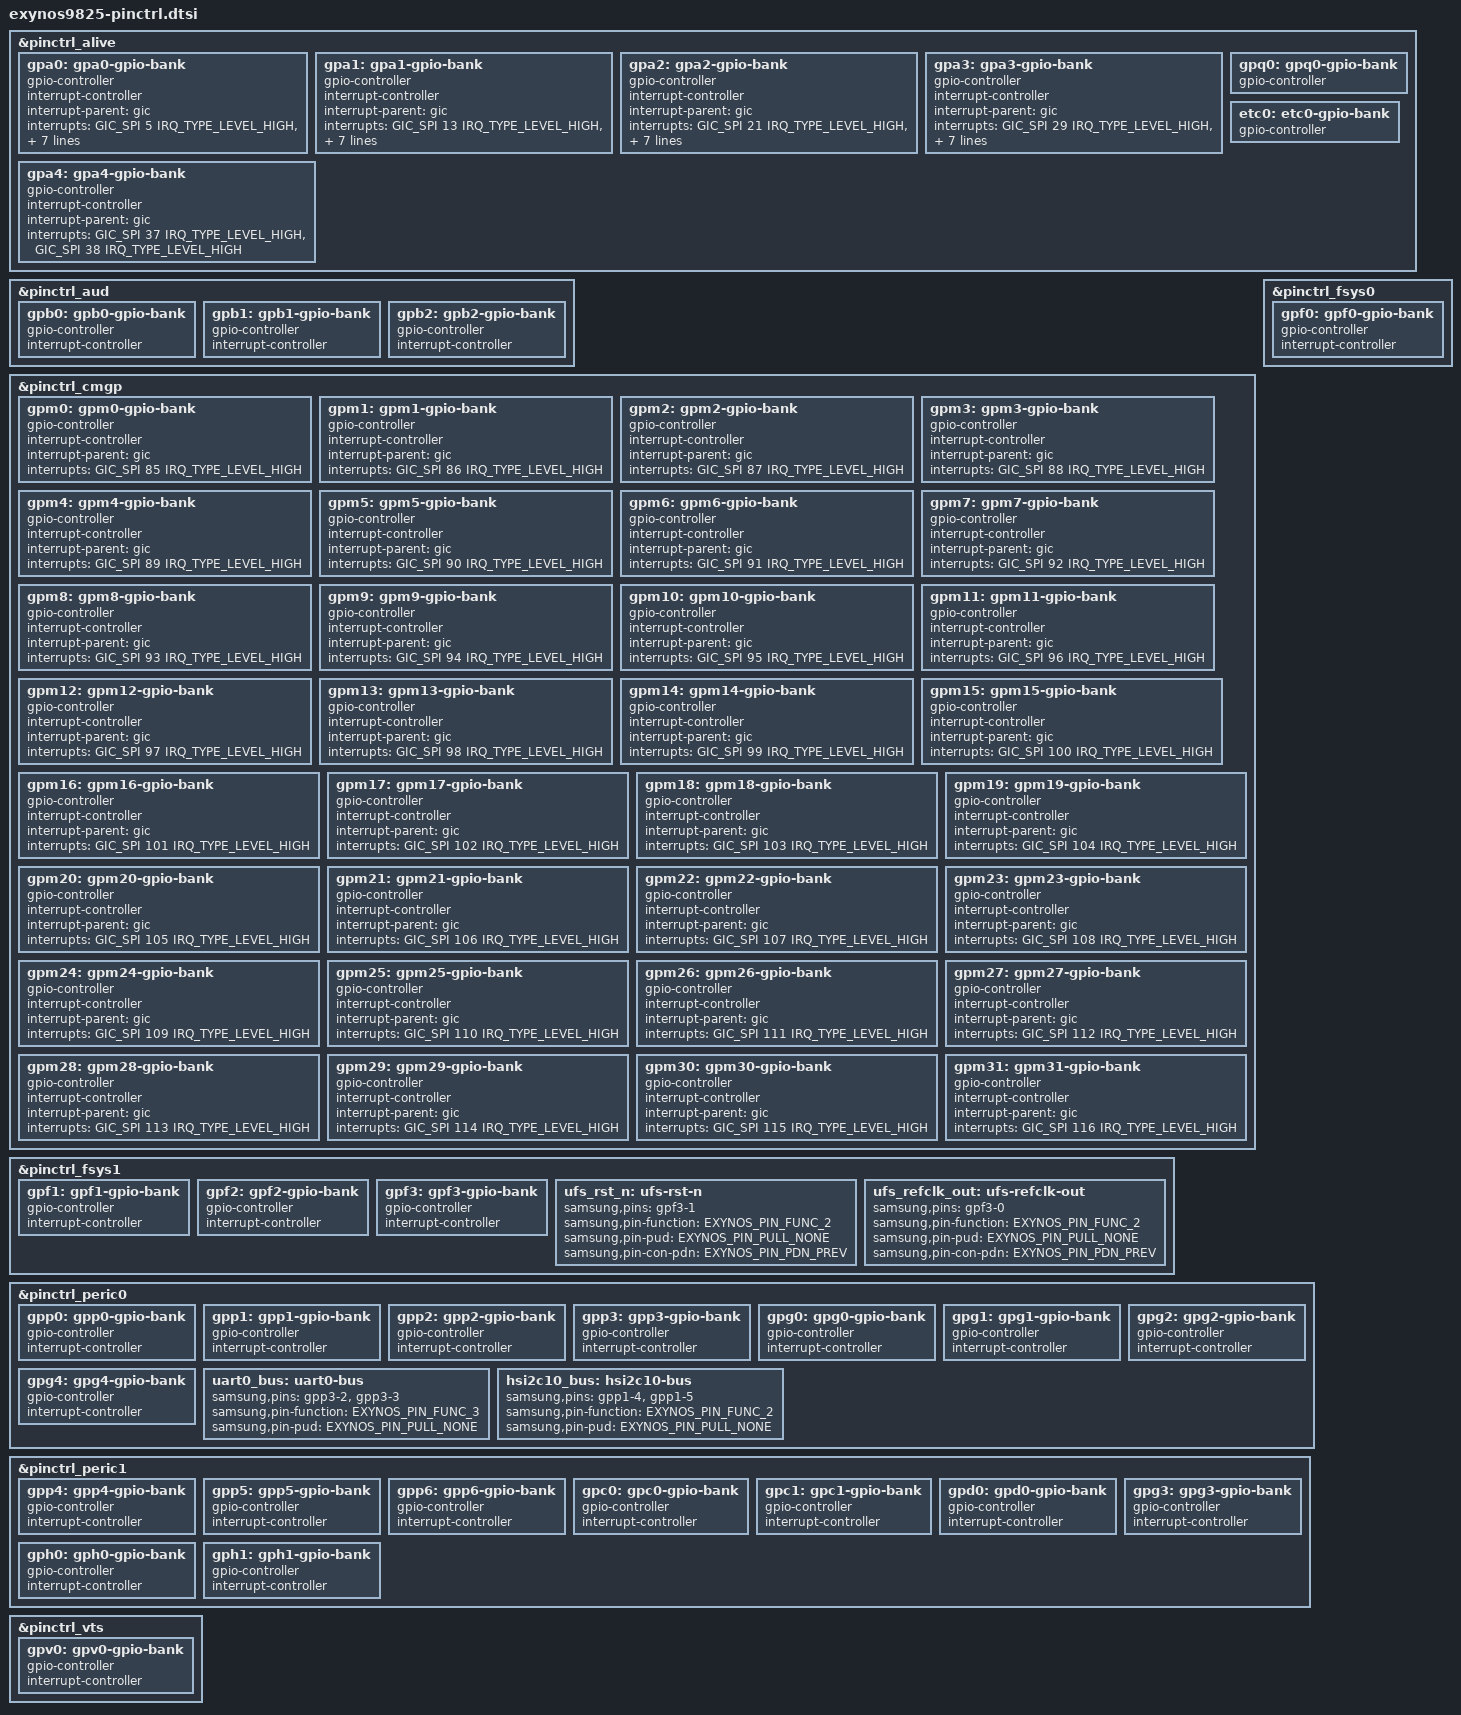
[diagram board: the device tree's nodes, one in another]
// SPDX-License-Identifier: GPL-2.0
/*
 * Samsung Exynos 9825 pin-mux and pin-config device tree source
 */

#include <dt-bindings/interrupt-controller/arm-gic.h>
#include "exynos-pinctrl.h"

&pinctrl_alive {
	gpa0: gpa0-gpio-bank {
		gpio-controller;
		#gpio-cells = <2>;

		interrupt-controller;
		#interrupt-cells = <2>;
		interrupt-parent = <&gic>;
		interrupts =
<GIC_SPI 5 IRQ_TYPE_LEVEL_HIGH>,
			     <GIC_SPI 6 IRQ_TYPE_LEVEL_HIGH>,
			     <GIC_SPI 7 IRQ_TYPE_LEVEL_HIGH>,
			     <GIC_SPI 8 IRQ_TYPE_LEVEL_HIGH>,
			     <GIC_SPI 9 IRQ_TYPE_LEVEL_HIGH>,
			     <GIC_SPI 10 IRQ_TYPE_LEVEL_HIGH>,
			     <GIC_SPI 11 IRQ_TYPE_LEVEL_HIGH>,
			     <GIC_SPI 12 IRQ_TYPE_LEVEL_HIGH>;
	};
	gpa1: gpa1-gpio-bank {
		gpio-controller;
		#gpio-cells = <2>;

		interrupt-controller;
		#interrupt-cells = <2>;
		interrupt-parent = <&gic>;
		interrupts =
<GIC_SPI 13 IRQ_TYPE_LEVEL_HIGH>,
			     <GIC_SPI 14 IRQ_TYPE_LEVEL_HIGH>,
			     <GIC_SPI 15 IRQ_TYPE_LEVEL_HIGH>,
			     <GIC_SPI 16 IRQ_TYPE_LEVEL_HIGH>,
			     <GIC_SPI 17 IRQ_TYPE_LEVEL_HIGH>,
			     <GIC_SPI 18 IRQ_TYPE_LEVEL_HIGH>,
			     <GIC_SPI 19 IRQ_TYPE_LEVEL_HIGH>,
			     <GIC_SPI 20 IRQ_TYPE_LEVEL_HIGH>;
	};
	gpa2: gpa2-gpio-bank {
		gpio-controller;
		#gpio-cells = <2>;

		interrupt-controller;
		#interrupt-cells = <2>;
		interrupt-parent = <&gic>;
		interrupts =
<GIC_SPI 21 IRQ_TYPE_LEVEL_HIGH>,
			     <GIC_SPI 22 IRQ_TYPE_LEVEL_HIGH>,
			     <GIC_SPI 23 IRQ_TYPE_LEVEL_HIGH>,
			     <GIC_SPI 24 IRQ_TYPE_LEVEL_HIGH>,
			     <GIC_SPI 25 IRQ_TYPE_LEVEL_HIGH>,
			     <GIC_SPI 26 IRQ_TYPE_LEVEL_HIGH>,
			     <GIC_SPI 27 IRQ_TYPE_LEVEL_HIGH>,
			     <GIC_SPI 28 IRQ_TYPE_LEVEL_HIGH>;
	};
	gpa3: gpa3-gpio-bank {
		gpio-controller;
		#gpio-cells = <2>;

		interrupt-controller;
		#interrupt-cells = <2>;
		interrupt-parent = <&gic>;
		interrupts =
<GIC_SPI 29 IRQ_TYPE_LEVEL_HIGH>,
			     <GIC_SPI 30 IRQ_TYPE_LEVEL_HIGH>,
			     <GIC_SPI 31 IRQ_TYPE_LEVEL_HIGH>,
			     <GIC_SPI 32 IRQ_TYPE_LEVEL_HIGH>,
			     <GIC_SPI 33 IRQ_TYPE_LEVEL_HIGH>,
			     <GIC_SPI 34 IRQ_TYPE_LEVEL_HIGH>,
			     <GIC_SPI 35 IRQ_TYPE_LEVEL_HIGH>,
			     <GIC_SPI 36 IRQ_TYPE_LEVEL_HIGH>;
	};
	gpa4: gpa4-gpio-bank {
		gpio-controller;
		#gpio-cells = <2>;

		interrupt-controller;
		#interrupt-cells = <2>;
		interrupt-parent = <&gic>;
		interrupts =
<GIC_SPI 37 IRQ_TYPE_LEVEL_HIGH>,
			     <GIC_SPI 38 IRQ_TYPE_LEVEL_HIGH>;
	};
	gpq0: gpq0-gpio-bank {
		gpio-controller;
		#gpio-cells = <2>;
	};
	etc0: etc0-gpio-bank {
		gpio-controller;
		#gpio-cells = <2>;
	};
};

&pinctrl_aud {
	gpb0: gpb0-gpio-bank {
		gpio-controller;
		#gpio-cells = <2>;

		interrupt-controller;
		#interrupt-cells = <2>;
	};
	gpb1: gpb1-gpio-bank {
		gpio-controller;
		#gpio-cells = <2>;

		interrupt-controller;
		#interrupt-cells = <2>;
	};
	gpb2: gpb2-gpio-bank {
		gpio-controller;
		#gpio-cells = <2>;

		interrupt-controller;
		#interrupt-cells = <2>;
	};
};

&pinctrl_cmgp {
	gpm0: gpm0-gpio-bank {
		gpio-controller;
		#gpio-cells = <2>;

		interrupt-controller;
		#interrupt-cells = <2>;
		interrupt-parent = <&gic>;
		interrupts =
<GIC_SPI 85 IRQ_TYPE_LEVEL_HIGH>;
	};
	gpm1: gpm1-gpio-bank {
		gpio-controller;
		#gpio-cells = <2>;

		interrupt-controller;
		#interrupt-cells = <2>;
		interrupt-parent = <&gic>;
		interrupts =
<GIC_SPI 86 IRQ_TYPE_LEVEL_HIGH>;
	};
	gpm2: gpm2-gpio-bank {
		gpio-controller;
		#gpio-cells = <2>;

		interrupt-controller;
		#interrupt-cells = <2>;
		interrupt-parent = <&gic>;
		interrupts =
<GIC_SPI 87 IRQ_TYPE_LEVEL_HIGH>;
	};
	gpm3: gpm3-gpio-bank {
		gpio-controller;
		#gpio-cells = <2>;

		interrupt-controller;
		#interrupt-cells = <2>;
		interrupt-parent = <&gic>;
		interrupts =
<GIC_SPI 88 IRQ_TYPE_LEVEL_HIGH>;
	};
	gpm4: gpm4-gpio-bank {
		gpio-controller;
		#gpio-cells = <2>;

		interrupt-controller;
		#interrupt-cells = <2>;
		interrupt-parent = <&gic>;
		interrupts =
<GIC_SPI 89 IRQ_TYPE_LEVEL_HIGH>;
	};
	gpm5: gpm5-gpio-bank {
		gpio-controller;
		#gpio-cells = <2>;

		interrupt-controller;
		#interrupt-cells = <2>;
		interrupt-parent = <&gic>;
		interrupts =
<GIC_SPI 90 IRQ_TYPE_LEVEL_HIGH>;
	};
	gpm6: gpm6-gpio-bank {
		gpio-controller;
		#gpio-cells = <2>;

		interrupt-controller;
		#interrupt-cells = <2>;
		interrupt-parent = <&gic>;
		interrupts =
<GIC_SPI 91 IRQ_TYPE_LEVEL_HIGH>;
	};
	gpm7: gpm7-gpio-bank {
		gpio-controller;
		#gpio-cells = <2>;

		interrupt-controller;
		#interrupt-cells = <2>;
		interrupt-parent = <&gic>;
		interrupts =
<GIC_SPI 92 IRQ_TYPE_LEVEL_HIGH>;
	};
	gpm8: gpm8-gpio-bank {
		gpio-controller;
		#gpio-cells = <2>;

		interrupt-controller;
		#interrupt-cells = <2>;
		interrupt-parent = <&gic>;
		interrupts =
<GIC_SPI 93 IRQ_TYPE_LEVEL_HIGH>;
	};
	gpm9: gpm9-gpio-bank {
		gpio-controller;
		#gpio-cells = <2>;

		interrupt-controller;
		#interrupt-cells = <2>;
		interrupt-parent = <&gic>;
		interrupts =
<GIC_SPI 94 IRQ_TYPE_LEVEL_HIGH>;
	};
	gpm10: gpm10-gpio-bank {
		gpio-controller;
		#gpio-cells = <2>;

		interrupt-controller;
		#interrupt-cells = <2>;
		interrupt-parent = <&gic>;
		interrupts =
<GIC_SPI 95 IRQ_TYPE_LEVEL_HIGH>;
	};
	gpm11: gpm11-gpio-bank {
		gpio-controller;
		#gpio-cells = <2>;

		interrupt-controller;
		#interrupt-cells = <2>;
		interrupt-parent = <&gic>;
		interrupts =
<GIC_SPI 96 IRQ_TYPE_LEVEL_HIGH>;
	};
	gpm12: gpm12-gpio-bank {
		gpio-controller;
		#gpio-cells = <2>;

		interrupt-controller;
		#interrupt-cells = <2>;
		interrupt-parent = <&gic>;
		interrupts =
<GIC_SPI 97 IRQ_TYPE_LEVEL_HIGH>;
	};
	gpm13: gpm13-gpio-bank {
		gpio-controller;
		#gpio-cells = <2>;

		interrupt-controller;
		#interrupt-cells = <2>;
		interrupt-parent = <&gic>;
		interrupts =
<GIC_SPI 98 IRQ_TYPE_LEVEL_HIGH>;
	};
	gpm14: gpm14-gpio-bank {
		gpio-controller;
		#gpio-cells = <2>;

		interrupt-controller;
		#interrupt-cells = <2>;
		interrupt-parent = <&gic>;
		interrupts =
<GIC_SPI 99 IRQ_TYPE_LEVEL_HIGH>;
	};
	gpm15: gpm15-gpio-bank {
		gpio-controller;
		#gpio-cells = <2>;

		interrupt-controller;
		#interrupt-cells = <2>;
		interrupt-parent = <&gic>;
		interrupts =
<GIC_SPI 100 IRQ_TYPE_LEVEL_HIGH>;
	};
	gpm16: gpm16-gpio-bank {
		gpio-controller;
		#gpio-cells = <2>;

		interrupt-controller;
		#interrupt-cells = <2>;
		interrupt-parent = <&gic>;
		interrupts =
<GIC_SPI 101 IRQ_TYPE_LEVEL_HIGH>;
	};
	gpm17: gpm17-gpio-bank {
		gpio-controller;
		#gpio-cells = <2>;

		interrupt-controller;
		#interrupt-cells = <2>;
		interrupt-parent = <&gic>;
		interrupts =
<GIC_SPI 102 IRQ_TYPE_LEVEL_HIGH>;
	};
	gpm18: gpm18-gpio-bank {
		gpio-controller;
		#gpio-cells = <2>;

		interrupt-controller;
		#interrupt-cells = <2>;
		interrupt-parent = <&gic>;
		interrupts =
<GIC_SPI 103 IRQ_TYPE_LEVEL_HIGH>;
	};
	gpm19: gpm19-gpio-bank {
		gpio-controller;
		#gpio-cells = <2>;

		interrupt-controller;
		#interrupt-cells = <2>;
		interrupt-parent = <&gic>;
		interrupts =
<GIC_SPI 104 IRQ_TYPE_LEVEL_HIGH>;
	};
	gpm20: gpm20-gpio-bank {
		gpio-controller;
		#gpio-cells = <2>;

		interrupt-controller;
		#interrupt-cells = <2>;
		interrupt-parent = <&gic>;
		interrupts =
<GIC_SPI 105 IRQ_TYPE_LEVEL_HIGH>;
	};
	gpm21: gpm21-gpio-bank {
		gpio-controller;
		#gpio-cells = <2>;

		interrupt-controller;
		#interrupt-cells = <2>;
		interrupt-parent = <&gic>;
		interrupts =
<GIC_SPI 106 IRQ_TYPE_LEVEL_HIGH>;
	};
	gpm22: gpm22-gpio-bank {
		gpio-controller;
		#gpio-cells = <2>;

		interrupt-controller;
		#interrupt-cells = <2>;
		interrupt-parent = <&gic>;
		interrupts =
<GIC_SPI 107 IRQ_TYPE_LEVEL_HIGH>;
	};
	gpm23: gpm23-gpio-bank {
		gpio-controller;
		#gpio-cells = <2>;

		interrupt-controller;
		#interrupt-cells = <2>;
		interrupt-parent = <&gic>;
		interrupts =
<GIC_SPI 108 IRQ_TYPE_LEVEL_HIGH>;
	};
	gpm24: gpm24-gpio-bank {
		gpio-controller;
		#gpio-cells = <2>;

		interrupt-controller;
		#interrupt-cells = <2>;
		interrupt-parent = <&gic>;
		interrupts =
<GIC_SPI 109 IRQ_TYPE_LEVEL_HIGH>;
	};
	gpm25: gpm25-gpio-bank {
		gpio-controller;
		#gpio-cells = <2>;

		interrupt-controller;
		#interrupt-cells = <2>;
		interrupt-parent = <&gic>;
		interrupts =
<GIC_SPI 110 IRQ_TYPE_LEVEL_HIGH>;
	};
	gpm26: gpm26-gpio-bank {
		gpio-controller;
		#gpio-cells = <2>;

		interrupt-controller;
		#interrupt-cells = <2>;
		interrupt-parent = <&gic>;
		interrupts =
<GIC_SPI 111 IRQ_TYPE_LEVEL_HIGH>;
	};
	gpm27: gpm27-gpio-bank {
		gpio-controller;
		#gpio-cells = <2>;

		interrupt-controller;
		#interrupt-cells = <2>;
		interrupt-parent = <&gic>;
		interrupts =
<GIC_SPI 112 IRQ_TYPE_LEVEL_HIGH>;
	};
	gpm28: gpm28-gpio-bank {
		gpio-controller;
		#gpio-cells = <2>;

		interrupt-controller;
		#interrupt-cells = <2>;
		interrupt-parent = <&gic>;
		interrupts =
<GIC_SPI 113 IRQ_TYPE_LEVEL_HIGH>;
	};
	gpm29: gpm29-gpio-bank {
		gpio-controller;
		#gpio-cells = <2>;

		interrupt-controller;
		#interrupt-cells = <2>;
		interrupt-parent = <&gic>;
		interrupts =
<GIC_SPI 114 IRQ_TYPE_LEVEL_HIGH>;
	};
	gpm30: gpm30-gpio-bank {
		gpio-controller;
		#gpio-cells = <2>;

		interrupt-controller;
		#interrupt-cells = <2>;
		interrupt-parent = <&gic>;
		interrupts =
<GIC_SPI 115 IRQ_TYPE_LEVEL_HIGH>;
	};
	gpm31: gpm31-gpio-bank {
		gpio-controller;
		#gpio-cells = <2>;

		interrupt-controller;
		#interrupt-cells = <2>;
		interrupt-parent = <&gic>;
		interrupts =
<GIC_SPI 116 IRQ_TYPE_LEVEL_HIGH>;
	};
};

&pinctrl_fsys0 {
	gpf0: gpf0-gpio-bank {
		gpio-controller;
		#gpio-cells = <2>;

		interrupt-controller;
		#interrupt-cells = <2>;
	};
};

&pinctrl_fsys1 {
	gpf1: gpf1-gpio-bank {
		gpio-controller;
		#gpio-cells = <2>;

		interrupt-controller;
		#interrupt-cells = <2>;
	};
	gpf2: gpf2-gpio-bank {
		gpio-controller;
		#gpio-cells = <2>;

		interrupt-controller;
		#interrupt-cells = <2>;
	};
	gpf3: gpf3-gpio-bank {
		gpio-controller;
		#gpio-cells = <2>;

		interrupt-controller;
		#interrupt-cells = <2>;
	};

	ufs_rst_n: ufs-rst-n {
		samsung,pins = "gpf3-1";
		samsung,pin-function = <EXYNOS_PIN_FUNC_2>;
		samsung,pin-pud = <EXYNOS_PIN_PULL_NONE>;
		samsung,pin-con-pdn = <EXYNOS_PIN_PDN_PREV>;
	};

	ufs_refclk_out: ufs-refclk-out {
		samsung,pins = "gpf3-0";
		samsung,pin-function = <EXYNOS_PIN_FUNC_2>;
		samsung,pin-pud = <EXYNOS_PIN_PULL_NONE>;
		samsung,pin-con-pdn = <EXYNOS_PIN_PDN_PREV>;
	};

};

&pinctrl_peric0 {
	gpp0: gpp0-gpio-bank {
		gpio-controller;
		#gpio-cells = <2>;

		interrupt-controller;
		#interrupt-cells = <2>;
	};
	gpp1: gpp1-gpio-bank {
		gpio-controller;
		#gpio-cells = <2>;

		interrupt-controller;
		#interrupt-cells = <2>;
	};
	gpp2: gpp2-gpio-bank {
		gpio-controller;
		#gpio-cells = <2>;

		interrupt-controller;
		#interrupt-cells = <2>;
	};
	gpp3: gpp3-gpio-bank {
		gpio-controller;
		#gpio-cells = <2>;

		interrupt-controller;
		#interrupt-cells = <2>;
	};
	gpg0: gpg0-gpio-bank {
		gpio-controller;
		#gpio-cells = <2>;

		interrupt-controller;
		#interrupt-cells = <2>;
	};
	gpg1: gpg1-gpio-bank {
		gpio-controller;
		#gpio-cells = <2>;

		interrupt-controller;
		#interrupt-cells = <2>;
	};
	gpg2: gpg2-gpio-bank {
		gpio-controller;
		#gpio-cells = <2>;

		interrupt-controller;
		#interrupt-cells = <2>;
	};
	gpg4: gpg4-gpio-bank {
		gpio-controller;
		#gpio-cells = <2>;

		interrupt-controller;
		#interrupt-cells = <2>;
	};

	uart0_bus: uart0-bus {
		samsung,pins = "gpp3-2", "gpp3-3";
		samsung,pin-function = <EXYNOS_PIN_FUNC_3>;
		samsung,pin-pud = <EXYNOS_PIN_PULL_NONE>;
	};

	hsi2c10_bus: hsi2c10-bus {
		samsung,pins = "gpp1-4", "gpp1-5";
		samsung,pin-function = <EXYNOS_PIN_FUNC_2>;
		samsung,pin-pud = <EXYNOS_PIN_PULL_NONE>;
	};

};

&pinctrl_peric1 {
	gpp4: gpp4-gpio-bank {
		gpio-controller;
		#gpio-cells = <2>;

		interrupt-controller;
		#interrupt-cells = <2>;
	};
	gpp5: gpp5-gpio-bank {
		gpio-controller;
		#gpio-cells = <2>;

		interrupt-controller;
		#interrupt-cells = <2>;
	};
	gpp6: gpp6-gpio-bank {
		gpio-controller;
		#gpio-cells = <2>;

		interrupt-controller;
		#interrupt-cells = <2>;
	};
	gpc0: gpc0-gpio-bank {
		gpio-controller;
		#gpio-cells = <2>;

		interrupt-controller;
		#interrupt-cells = <2>;
	};
	gpc1: gpc1-gpio-bank {
		gpio-controller;
		#gpio-cells = <2>;

		interrupt-controller;
		#interrupt-cells = <2>;
	};
	gpd0: gpd0-gpio-bank {
		gpio-controller;
		#gpio-cells = <2>;

		interrupt-controller;
		#interrupt-cells = <2>;
	};
	gpg3: gpg3-gpio-bank {
		gpio-controller;
		#gpio-cells = <2>;

		interrupt-controller;
		#interrupt-cells = <2>;
	};
	gph0: gph0-gpio-bank {
		gpio-controller;
		#gpio-cells = <2>;

		interrupt-controller;
		#interrupt-cells = <2>;
	};
	gph1: gph1-gpio-bank {
		gpio-controller;
		#gpio-cells = <2>;

		interrupt-controller;
		#interrupt-cells = <2>;
	};
};

&pinctrl_vts {
	gpv0: gpv0-gpio-bank {
		gpio-controller;
		#gpio-cells = <2>;

		interrupt-controller;
		#interrupt-cells = <2>;
	};
};
